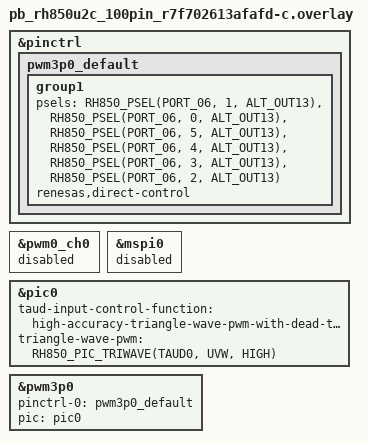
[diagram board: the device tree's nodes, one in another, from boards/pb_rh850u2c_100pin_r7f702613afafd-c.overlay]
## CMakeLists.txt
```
# SPDX-License-Identifier: Apache-2.0

cmake_minimum_required(VERSION 3.20.0)

find_package(Zephyr REQUIRED HINTS $ENV{ZEPHYR_BASE})
project(pwm3p)

target_sources(app PRIVATE src/main.c)
```

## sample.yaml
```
sample:
  name: PWM3P (3-phase PWM)
  description: >
    Minimal PWM3P usage example: configure period/duty, enable the 6
    complementary U/V/W outputs, and sweep the duty cycle.
common:
  tags:
    - drivers
    - pwm
    - pwm3p
  harness: console
  harness_config:
    type: multi_line
    ordered: true
    regex:
      - "PWM3P ready: period=(.*) counts, counter clock=(.*) Hz \\(PWM freq=(.*) Hz\\)"
      - "PWM3P output enabled, sweeping duty (.*)%..(.*)%"
  depends_on: pwm
tests:
  sample.drivers.pwm3p:
    platform_allow:
      - pb_rh850u2a_176pin/r7f702302fafk-c
      - pb_rh850u2a_292pin/r7f702300afaba-c
      - pb_rh850u2a_292pin/r7f702300bfaba-c
      - pb_rh850u2a_292pin/r7f702300eaba-c
      - pb_rh850u2a_292pin/r7f702301afabg-c
      - pb_rh850u2a_292pin/r7f702301bfabg-c
      - pb_rh850u2a_292pin/r7f702301eabg-c
      - pb_rh850u2a_292pin/r7f702302fabb-c
      - pb_rh850u2a_373pin/r7f702300aebbb-c
      - pb_rh850u2a_373pin/r7f702300bebbb-c
      - pb_rh850u2a_373pin/r7f702300ebbb-c
      - pb_rh850u2a_373pin/r7f702301aebba-c
      - pb_rh850u2a_373pin/r7f702301bebba-c
      - pb_rh850u2a_373pin/r7f702301ebba-c
      - pb_rh850u2a_516pin/r7f702300aebbc-c
      - pb_rh850u2a_516pin/r7f702300bebbc-c
      - pb_rh850u2a_516pin/r7f702300ebbg-c
      - pb_rh850u2b_292pin/r7f70254xafabb-c
      - pb_rh850u2b_292pin/r7f70254xfabb-c
      - pb_rh850u2b_292pin/r7f70255xafabb-c
      - pb_rh850u2b_292pin/r7f70255xbfabb-c
      - pb_rh850u2b_292pin/r7f70255xfabb-c
      - pb_rh850u2b_373pin/r7f70254xafaba-c
      - pb_rh850u2b_373pin/r7f70254xfaba-c
      - pb_rh850u2b_468pin/r7f70254xafabg-c
      - pb_rh850u2b_468pin/r7f70254xfabg-c
      - pb_rh850u2c_100pin/r7f702606afafd-c
      - pb_rh850u2c_100pin/r7f702608afafd-c
      - pb_rh850u2c_100pin/r7f702613afafd-c
      - pb_rh850u2c_100pin/r7f702616afafd-c
      - pb_rh850u2c_144pin/r7f702606afafb-c
      - pb_rh850u2c_144pin/r7f702606afafm-c
      - pb_rh850u2c_144pin/r7f702614afafb-c
      - pb_rh850u2c_144pin/r7f702614afafm-c
      - pb_rh850u2c_144pin/r7f702615afafb-c
      - pb_rh850u2c_144pin/r7f702615afafm-c
      - pb_rh850u2c_144pin/r7f702616afafb-c
      - pb_rh850u2c_144pin/r7f702616afafm-c
      - pb_rh850u2c_292pin/r7f702600afabb-c
      - pb_rh850u2c_292pin/r7f702606afabb-c
      - pb_rh850u2c_292pin/r7f702613afabb-c
      - pb_rh850u2c_292pin/r7f702616afabb-c
    integration_platforms:
      - pb_rh850u2a_516pin/r7f702300bebbc-c
```

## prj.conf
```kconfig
CONFIG_PWM3P=y
```

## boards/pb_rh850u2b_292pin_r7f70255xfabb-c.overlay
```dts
/*
 * Copyright (c) 2026 Renesas Electronics Corporation
 * SPDX-License-Identifier: Apache-2.0
 */

#include <zephyr/dt-bindings/pic/renesas/pic-rh850-common.h>
#include <dt-bindings/pinctrl/renesas/pinctrl-rh850u2b.h>

&pinctrl {
	pwm3p0_default: pwm3p0_default {
		group1 {
			psels = <RH850_PSEL(PORT_12, 5, ALT_OUT10)>,  /* U high */
				<RH850_PSEL(PORT_12, 3, ALT_OUT11)>,  /* U low  */
				<RH850_PSEL(PORT_12, 0, ALT_OUT11)>,  /* V high */
				<RH850_PSEL(PORT_12, 1, ALT_OUT11)>,  /* V low  */
				<RH850_PSEL(PORT_12, 2, ALT_OUT11)>,  /* W high */
				<RH850_PSEL(PORT_12, 6,  ALT_OUT1)>;  /* W low  */
			renesas,direct-control;
			drive-strength = "medium";
		};
	};
};

/*
 * Opt-in: enable the PIC and PWM3P nodes, they are disabled at board level. The PWM3P master
 * channel is the same timer channel used by pwm0_ch2, so disable the pwm0_ch0 group so that it
 * does not conflict with PWM3P.
 */
&pwm0_ch0 {
	status = "disabled";
};

&pic0 {
	taud-input-control-function = "high-accuracy-triangle-wave-pwm-with-dead-time";
	triangle-wave-pwm = <RH850_PIC_TRIWAVE(TAUD0, UVW, HIGH)>;
	status = "okay";
};

&pwm3p0 {
	pinctrl-0 = <&pwm3p0_default>;
	pinctrl-names = "default";
	pic = <&pic0>;
	status = "okay";
};
```

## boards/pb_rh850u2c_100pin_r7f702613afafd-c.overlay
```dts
/*
 * Copyright (c) 2026 Renesas Electronics Corporation
 * SPDX-License-Identifier: Apache-2.0
 */

#include <zephyr/dt-bindings/pic/renesas/pic-rh850-common.h>
#include <dt-bindings/pinctrl/renesas/pinctrl-rh850u2c.h>

&pinctrl {
	pwm3p0_default: pwm3p0_default {
		group1 {
			psels = <RH850_PSEL(PORT_06, 1, ALT_OUT13)>,  /* U high */
				<RH850_PSEL(PORT_06, 0, ALT_OUT13)>,  /* U low  */
				<RH850_PSEL(PORT_06, 5, ALT_OUT13)>,  /* V high */
				<RH850_PSEL(PORT_06, 4, ALT_OUT13)>,  /* V low  */
				<RH850_PSEL(PORT_06, 3, ALT_OUT13)>,  /* W high */
				<RH850_PSEL(PORT_06, 2, ALT_OUT13)>;  /* W low  */
			renesas,direct-control;
		};
	};
};

/*
 * Opt-in: enable the PIC and PWM3P nodes, they are disabled at board level. The PWM3P master
 * channel is the same timer channel used by pwm0_ch2, so disable the pwm0_ch0 group. Pin P06_5
 * is also used by mspi0. Disable them so that they do not conflict with PWM3P.
 */
&pwm0_ch0 {
	status = "disabled";
};

&mspi0 {
	status = "disabled";
};

&pic0 {
	taud-input-control-function = "high-accuracy-triangle-wave-pwm-with-dead-time";
	triangle-wave-pwm = <RH850_PIC_TRIWAVE(TAUD0, UVW, HIGH)>;
	status = "okay";
};

&pwm3p0 {
	pinctrl-0 = <&pwm3p0_default>;
	pinctrl-names = "default";
	pic = <&pic0>;
	status = "okay";
};
```

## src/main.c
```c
/*
 * Copyright (c) 2026 Renesas Electronics Corporation
 *
 * SPDX-License-Identifier: Apache-2.0
 */

#include <zephyr/kernel.h>
#include <zephyr/device.h>
#include <zephyr/sys/atomic.h>
#include <zephyr/drivers/pwm3p.h>
#include <zephyr/sys/printk.h>

#define PWM3P_NODE DT_NODELABEL(pwm3p0)

/* Duty sweeps between 25% and 75% of the period, 5% per step, once per second. */
#define DUTY_MIN_PERCENT  25
#define DUTY_MAX_PERCENT  75
#define DUTY_STEP_PERCENT 5

static atomic_t cycle_count;

static void pwm3p_cycle_callback(const struct device *dev, void *user_data)
{
	ARG_UNUSED(dev);
	ARG_UNUSED(user_data);

	atomic_inc(&cycle_count);
}

int main(void)
{
	const struct device *pwm3p = DEVICE_DT_GET(PWM3P_NODE);
	uint32_t period_cycles;
	uint64_t cycles_per_sec;
	int duty_percent = DUTY_MIN_PERCENT;
	int step = DUTY_STEP_PERCENT;
	int ret;

	if (!device_is_ready(pwm3p)) {
		printk("PWM3P device is not ready\n");
		return 0;
	}

	ret = pwm3p_get_period_cycles(pwm3p, &period_cycles);
	if (ret < 0) {
		printk("pwm3p_get_period_cycles failed: %d\n", ret);
		return 0;
	}

	ret = pwm3p_get_cycles_per_sec(pwm3p, &cycles_per_sec);
	if (ret < 0) {
		printk("pwm3p_get_cycles_per_sec failed: %d\n", ret);
		return 0;
	}

	printk("PWM3P ready: period=%u counts, counter clock=%llu Hz (PWM freq=%llu Hz)\n",
	       period_cycles, cycles_per_sec, (uint64_t)cycles_per_sec / period_cycles);

	/* Optional: a device may not expose a cycle-end interrupt (no 'interrupts' property
	 * in its devicetree node), in which case this simply reports -ENOTSUP.
	 */
	ret = pwm3p_set_callback(pwm3p, pwm3p_cycle_callback, NULL);
	if (ret == 0) {
		printk("Cycle-end callback registered\n");
	} else if (ret == -ENOTSUP) {
		printk("Cycle-end callback not supported on this instance\n");
	} else {
		printk("pwm3p_set_callback failed: %d\n", ret);
	}

	ret = pwm3p_set_duty_cycles(pwm3p, period_cycles / 2U, period_cycles / 2U,
				     period_cycles / 2U);
	if (ret < 0) {
		printk("pwm3p_set_duty_cycles failed: %d\n", ret);
		return 0;
	}

	ret = pwm3p_enable_output(pwm3p, true);
	if (ret < 0) {
		printk("pwm3p_enable_output failed: %d\n", ret);
		return 0;
	}

	printk("PWM3P output enabled, sweeping duty %d%%..%d%%\n", DUTY_MIN_PERCENT,
	       DUTY_MAX_PERCENT);

	while (1) {
		uint32_t duty_cycles = (uint32_t)(((uint64_t)period_cycles * duty_percent) / 100U);

		ret = pwm3p_set_duty_cycles(pwm3p, duty_cycles, duty_cycles, duty_cycles);
		if (ret < 0) {
			printk("pwm3p_set_duty_cycles failed: %d\n", ret);
		}

		printk("duty=%d%% (%u counts), cycle_count=%ld\n", duty_percent, duty_cycles,
		       (long)atomic_get(&cycle_count));

		if (duty_percent == DUTY_MAX_PERCENT) {
			step = -DUTY_STEP_PERCENT;
		} else if (duty_percent == DUTY_MIN_PERCENT) {
			step = DUTY_STEP_PERCENT;
		}
		duty_percent += step;

		k_sleep(K_SECONDS(1));
	}

	return 0;
}
```
